VERSION ""

NS_ :

BS_:

BU_: SDV_Tester SDV_M_CORE0
VAL_TABLE_ Gear_state 4 "Invalid" 3 "D" 2 "N" 1 "R" 0 "P" ;
VAL_TABLE_ powerState 23 "PWSM_STATE_MSG_SHUTDOWN_DONE" 22 "PWSM_MSG_STATE_NO_RESPONSE" 21 "PWSM_STATE_MSG_RX_ID11" 20 "PWSM_STATE_MSG_TX_ID4" 19 "PWSM_STATE_MSG_RX_ID8" 18 "PWSM_STATE_MSG_RX_ID2" 17 "PWSM_STATE_MSG_TX_ID1" 0 "PWSM_MSG_STATE_IDLE" ;
VAL_TABLE_ Exit_Request_stauts 1 "Quit request" 0 "No Quit request" ;
VAL_TABLE_ KST_KL_15 1 "KL15 ON" 0 "KL15 OFF" ;

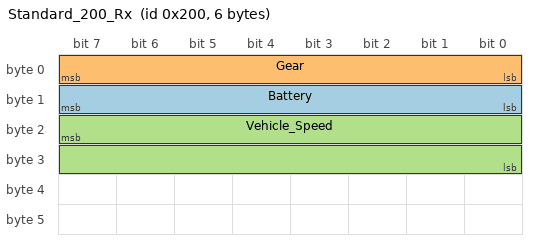
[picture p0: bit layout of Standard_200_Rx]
BO_ 512 Standard_200_Rx: 6 SDV_Tester
 SG_ Battery : 15|8@0+ (1,0) [0|100] "%" Vector__XXX
 SG_ Gear : 7|8@0+ (1,0) [0|4] "" Vector__XXX
 SG_ Vehicle_Speed : 23|16@0- (0.01,0) [-327.68|327.67] "km/h" Vector__XXX

BO_ 256 Standard_100_Tx: 1 SDV_M_CORE0
 SG_ Power_Msgstate : 7|8@0+ (1,0) [0|1] "" Vector__XXX

BA_DEF_ BO_  "GenMsgSendType" ENUM  "Cycle","cycle","vector_leerstring","Event";
BA_DEF_ BO_  "GenMsgCycleTime" INT 0 65535;
BA_DEF_ BO_  "GenSigSendType" ENUM  "Cycle","cycle","vector_leerstring","Event";
BA_DEF_  "BusType" STRING ;
BA_DEF_DEF_  "GenMsgSendType" "Cycle";
BA_DEF_DEF_  "GenMsgCycleTime" 100;
BA_DEF_DEF_  "GenSigSendType" "Cycle";
BA_DEF_DEF_  "BusType" "CAN";
VAL_ 512 Gear 4 "Invalid" 3 "D" 2 "N" 1 "R" 0 "P" ;
VAL_ 256 Power_Msgstate 23 "PWSM_STATE_MSG_SHUTDOWN_DONE" 22 "PWSM_MSG_STATE_NO_RESPONSE" 21 "PWSM_STATE_MSG_RX_ID11" 20 "PWSM_STATE_MSG_TX_ID4" 19 "PWSM_STATE_MSG_RX_ID8" 18 "PWSM_STATE_MSG_RX_ID2" 17 "PWSM_STATE_MSG_TX_ID1" 0 "PWSM_MSG_STATE_IDLE" ;
